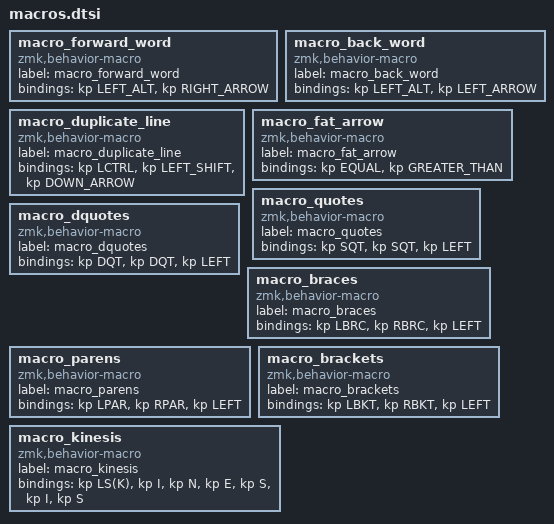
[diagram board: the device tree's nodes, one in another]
macro_forward_word: macro_forward_word{
compatible = "zmk,behavior-macro";
label = "macro_forward_word";
#binding-cells = <0>;
bindings = <&kp LEFT_ALT>, <&kp RIGHT_ARROW>;
};
macro_back_word: macro_back_word{
compatible = "zmk,behavior-macro";
label = "macro_back_word";
#binding-cells = <0>;
bindings = <&kp LEFT_ALT>, <&kp LEFT_ARROW>;
};
macro_duplicate_line: macro_duplicate_line{
compatible = "zmk,behavior-macro";
label = "macro_duplicate_line";
#binding-cells = <0>;
bindings = <&kp LCTRL>, <&kp LEFT_SHIFT>, <&kp DOWN_ARROW>;
};
macro_fat_arrow: macro_fat_arrow{
compatible = "zmk,behavior-macro";
label = "macro_fat_arrow";
#binding-cells = <0>;
bindings = <&kp EQUAL>, <&kp GREATER_THAN>;
};
macro_quotes: macro_quotes{
compatible = "zmk,behavior-macro";
label = "macro_quotes";
#binding-cells = <0>;
bindings = <&kp SQT>, <&kp SQT>, <&kp LEFT>;
};
macro_dquotes: macro_dquotes{
compatible = "zmk,behavior-macro";
label = "macro_dquotes";
#binding-cells = <0>;
bindings = <&kp DQT>, <&kp DQT>, <&kp LEFT>;
};
macro_braces: macro_braces{
compatible = "zmk,behavior-macro";
label = "macro_braces";
#binding-cells = <0>;
bindings = <&kp LBRC>, <&kp RBRC>, <&kp LEFT>;
};
macro_parens: macro_parens{
compatible = "zmk,behavior-macro";
label = "macro_parens";
#binding-cells = <0>;
bindings = <&kp LPAR>, <&kp RPAR>, <&kp LEFT>;
};
macro_brackets: macro_brackets{
compatible = "zmk,behavior-macro";
label = "macro_brackets";
#binding-cells = <0>;
bindings = <&kp LBKT>, <&kp RBKT>, <&kp LEFT>;
};
macro_kinesis: macro_kinesis{
compatible = "zmk,behavior-macro";
label = "macro_kinesis";
#binding-cells = <0>;
bindings = <&kp LS(K)>, <&kp I>, <&kp N>, <&kp E>, <&kp S>, <&kp I>, <&kp S>;
};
